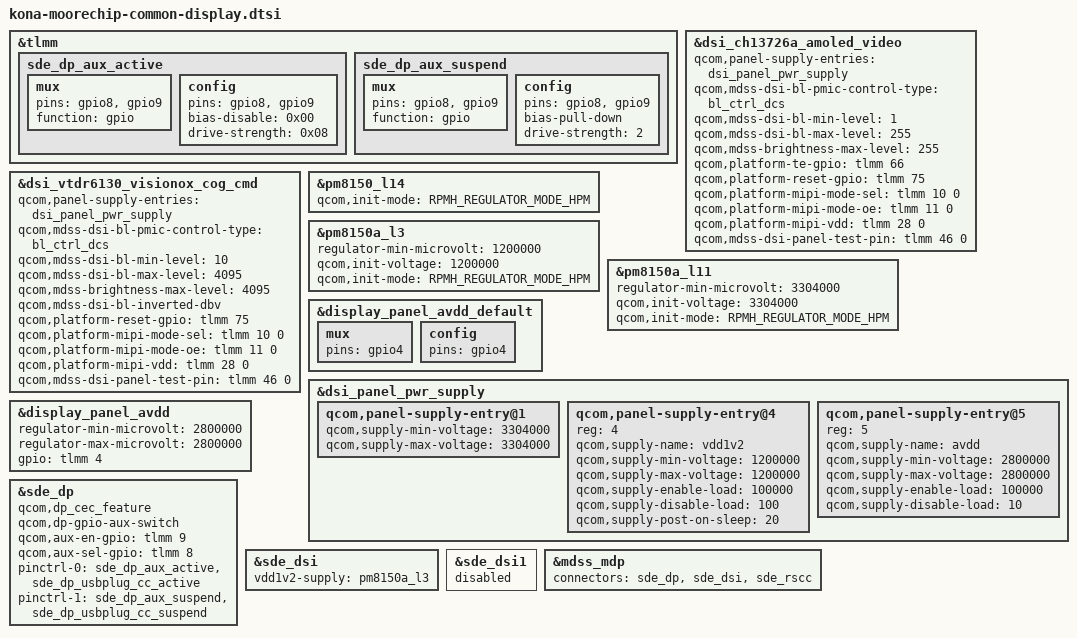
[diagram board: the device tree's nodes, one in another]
#include <dt-bindings/regulator/qcom,rpmh-regulator-levels.h>
#include "dsi-panel-ch13726a-amoled-video.dtsi"
#include "dsi-panel-vtdr6130-visionox-cog-cmd.dtsi"

&tlmm {
	sde_dp_aux_active: sde_dp_aux_active {
		mux {
			pins = "gpio8", "gpio9";
			function = "gpio";
		};

		config {
			pins = "gpio8", "gpio9";
			bias-disable = <0x00>;
			drive-strength = <0x08>;
		};
	};

	sde_dp_aux_suspend: sde_dp_aux_suspend {
		mux {
			pins = "gpio8", "gpio9";
			function = "gpio";
		};

		config {
			pins = "gpio8", "gpio9";
			bias-pull-down;         /* PULL DOWN */
			drive-strength = <2>;   /* 2 MA */
		};
	};
};

&dsi_ch13726a_amoled_video {
	qcom,panel-supply-entries = <&dsi_panel_pwr_supply>;
	qcom,mdss-dsi-bl-pmic-control-type = "bl_ctrl_dcs";
	qcom,mdss-dsi-bl-min-level = <1>;
	qcom,mdss-dsi-bl-max-level = <255>;
	qcom,mdss-brightness-max-level = <255>;
	qcom,platform-te-gpio = <&tlmm 66 0>;
	qcom,platform-reset-gpio = <&tlmm 75 0>;
	qcom,platform-mipi-mode-sel = <&tlmm 10 0>;
	qcom,platform-mipi-mode-oe = <&tlmm 11 0>;
	qcom,platform-mipi-vdd = <&tlmm 28 0>;
	qcom,mdss-dsi-panel-test-pin = <&tlmm 46 0>;
};

&dsi_vtdr6130_visionox_cog_cmd {
	qcom,panel-supply-entries = <&dsi_panel_pwr_supply>;
	qcom,mdss-dsi-bl-pmic-control-type = "bl_ctrl_dcs";
	qcom,mdss-dsi-bl-min-level = <10>;
	qcom,mdss-dsi-bl-max-level = <4095>;
	qcom,mdss-brightness-max-level = <4095>;
	qcom,mdss-dsi-bl-inverted-dbv;
	qcom,platform-reset-gpio = <&tlmm 75 0>;
	qcom,platform-mipi-mode-sel = <&tlmm 10 0>;
	qcom,platform-mipi-mode-oe = <&tlmm 11 0>;
	qcom,platform-mipi-vdd = <&tlmm 28 0>;
	qcom,mdss-dsi-panel-test-pin = <&tlmm 46 0>;
};

// display vddio
&pm8150_l14 {
	qcom,init-mode = <RPMH_REGULATOR_MODE_HPM>;
};

// display vdd1v2
&pm8150a_l3 {
	regulator-min-microvolt = <1200000>;
	qcom,init-voltage = <1200000>;
	qcom,init-mode = <RPMH_REGULATOR_MODE_HPM>;
};

// display vdd
&pm8150a_l11 {
	regulator-min-microvolt = <3304000>;
	qcom,init-voltage = <3304000>;
	qcom,init-mode = <RPMH_REGULATOR_MODE_HPM>;
};

&display_panel_avdd_default {
	mux {
		pins = "gpio4";
	};

	config {
		pins = "gpio4";
	};
};

&dsi_panel_pwr_supply {
	qcom,panel-supply-entry@1 {
		qcom,supply-min-voltage = <3304000>;
		qcom,supply-max-voltage = <3304000>;
	};

	qcom,panel-supply-entry@4 {
		reg = <4>;
		qcom,supply-name = "vdd1v2";
		qcom,supply-min-voltage = <1200000>;
		qcom,supply-max-voltage = <1200000>;
		qcom,supply-enable-load = <100000>;
		qcom,supply-disable-load = <100>;
		qcom,supply-post-on-sleep = <20>;
	};

	qcom,panel-supply-entry@5 {
		reg = <5>;
		qcom,supply-name = "avdd";
		qcom,supply-min-voltage = <2800000>;
		qcom,supply-max-voltage = <2800000>;
		qcom,supply-enable-load = <100000>;
		qcom,supply-disable-load = <10>;
	};
};

&display_panel_avdd {
	regulator-min-microvolt = <2800000>;
	regulator-max-microvolt = <2800000>;
	gpio = <&tlmm 4 0>;
};

&sde_dp {
	qcom,dp_cec_feature;
	/delete-property/ qcom,dp-aux-switch;
	qcom,dp-gpio-aux-switch;
	qcom,aux-en-gpio = <&tlmm 9 0>;
	qcom,aux-sel-gpio = <&tlmm 8 0>;
	pinctrl-0 = <&sde_dp_aux_active &sde_dp_usbplug_cc_active>;
	pinctrl-1 = <&sde_dp_aux_suspend &sde_dp_usbplug_cc_suspend>;
};

&sde_dsi {
	vdd1v2-supply = <&pm8150a_l3>;
	/delete-property/ lab-supply;
	/delete-property/ ibb-supply;
};

&sde_dsi1 {
	status = "disabled";
};

&mdss_mdp {
	connectors = <&sde_dp &sde_dsi &sde_rscc>;
};
